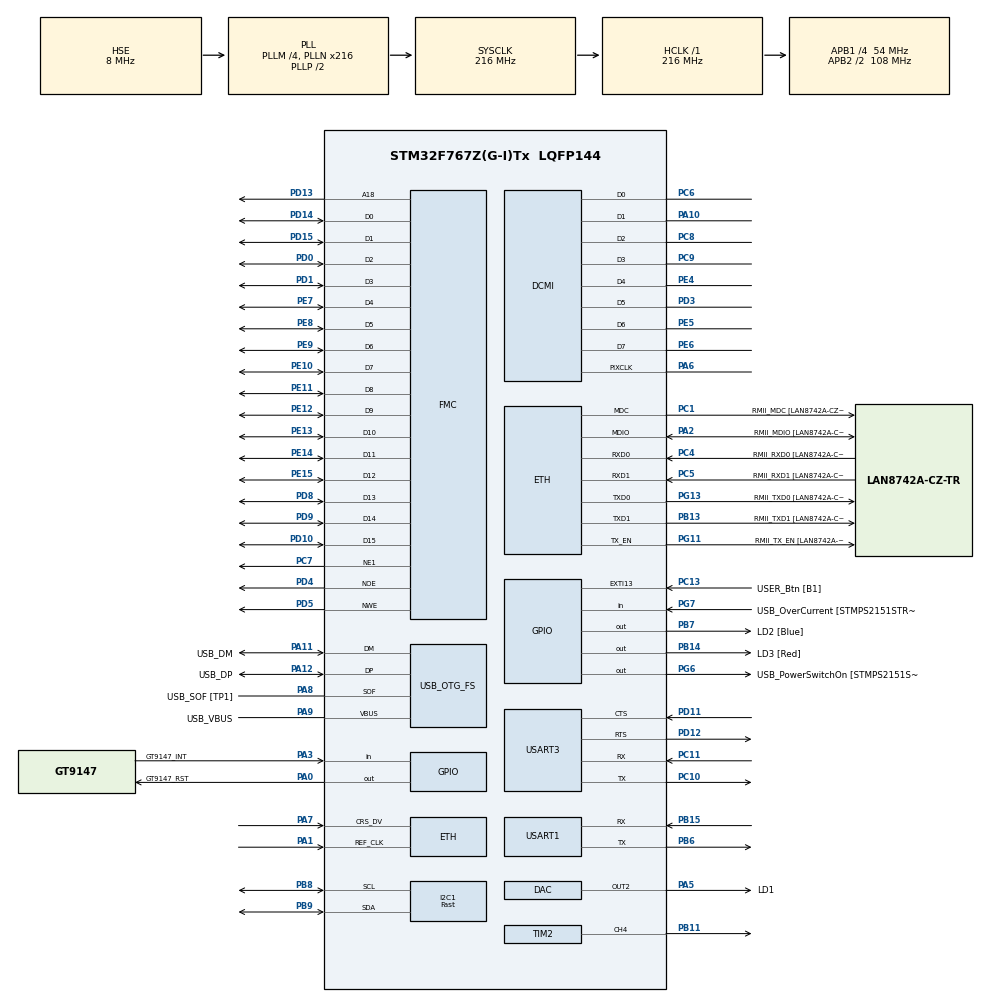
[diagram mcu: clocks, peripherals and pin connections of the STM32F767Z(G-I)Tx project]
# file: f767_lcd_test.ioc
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CORTEX_M7.ART_ACCLERATOR_ENABLE=1
CORTEX_M7.AccessPermission-Cortex_Memory_Protection_Unit_Region0_Settings=MPU_REGION_FULL_ACCESS
CORTEX_M7.BaseAddress-Cortex_Memory_Protection_Unit_Region0_Settings=0x20010000
CORTEX_M7.CPU_DCache=Enabled
CORTEX_M7.CPU_ICache=Enabled
CORTEX_M7.Enable-Cortex_Memory_Protection_Unit_Region0_Settings=MPU_REGION_ENABLE
CORTEX_M7.IsShareable-Cortex_Memory_Protection_Unit_Region0_Settings=MPU_ACCESS_SHAREABLE
CORTEX_M7.MPU_Control=MPU_HFNMI_PRIVDEF
CORTEX_M7.PREFETCH_ENABLE=1
CORTEX_M7.Size-Cortex_Memory_Protection_Unit_Region0_Settings=MPU_REGION_SIZE_4GB
DCMI.JPEGMode=DCMI_JPEG_DISABLE
ETH.MediaInterface=ETH_MEDIA_INTERFACE_RMII
FMC.DataSetupTime1=80
FMC.ExtendedAddressSetupTime1=1
FMC.ExtendedBusTurnAroundDuration1=1
FMC.ExtendedDataSetupTime1=2
FMC.ExtendedMode1=FMC_EXTENDED_MODE_ENABLE
I2C1.I2C_Speed_Mode=I2C_Fast
I2C1.Speed=400
I2C1.Timing=0x6000030D
Mcu.Family=STM32F7
Mcu.Name=STM32F767Z(G-I)Tx
Mcu.Package=LQFP144
NVIC.PriorityGroup=NVIC_PRIORITYGROUP_4
NVIC.USART3_IRQn=true\:0\:0\:false\:false\:true
PA0/WKUP.GPIO_Label=GT9147_RST
PA0/WKUP.PinState=GPIO_PIN_SET
PA0/WKUP.Signal=GPIO_Output
PA1.Mode=RMII
PA1.Signal=ETH_REF_CLK
PA10.Mode=Slave_8_bits_Embedded_Synchro
PA10.Signal=DCMI_D1
PA11.GPIO_Label=USB_DM
PA11.Mode=Host_Only
PA11.Signal=USB_OTG_FS_DM
PA12.GPIO_Label=USB_DP
PA12.Mode=Host_Only
PA12.Signal=USB_OTG_FS_DP
PA13.GPIO_Label=TMS
PA13.Mode=Trace_Asynchronous_SW
PA13.Signal=SYS_JTMS-SWDIO
PA14.GPIO_Label=TCK
PA14.Mode=Trace_Asynchronous_SW
PA14.Signal=SYS_JTCK-SWCLK
PA2.GPIO_Label=RMII_MDIO [LAN8742A-CZ-TR_MDIO]
PA2.Mode=RMII
PA2.Signal=ETH_MDIO
PA3.GPIO_Label=GT9147_INT
PA3.Signal=GPIO_Input
PA5.GPIO_Label=LD1
PA5.Signal=COMP_DAC2_group
PA6.Mode=Slave_8_bits_Embedded_Synchro
PA6.Signal=DCMI_PIXCLK
PA7.Mode=RMII
PA7.Signal=ETH_CRS_DV
PA8.GPIO_Label=USB_SOF [TP1]
PA8.Mode=Activate_SOF_FS
PA8.Signal=USB_OTG_FS_SOF
PA9.GPIO_Label=USB_VBUS
PA9.Mode=Activate_VBUS
PA9.Signal=USB_OTG_FS_VBUS
PB11.Signal=S_TIM2_CH4
PB13.GPIO_Label=RMII_TXD1 [LAN8742A-CZ-TR_TXD1]
PB13.Mode=RMII
PB13.Signal=ETH_TXD1
PB14.GPIO_Label=LD3 [Red]
PB14.Signal=GPIO_Output
PB15.Mode=Asynchronous
PB15.Signal=USART1_RX
PB3.GPIO_Label=SW0
PB3.Mode=Trace_Asynchronous_SW
PB3.Signal=SYS_JTDO-SWO
PB6.Mode=Asynchronous
PB6.Signal=USART1_TX
PB7.GPIO_Label=LD2 [Blue]
PB7.Signal=GPIO_Output
PB8.Mode=I2C
PB8.Signal=I2C1_SCL
PB9.Mode=I2C
PB9.Signal=I2C1_SDA
PC1.GPIO_Label=RMII_MDC [LAN8742A-CZ-TR_MDC]
PC1.Mode=RMII
PC1.Signal=ETH_MDC
PC10.Mode=Asynchronous
PC10.Signal=USART3_TX
PC11.Mode=Asynchronous
PC11.Signal=USART3_RX
PC13.GPIO_Label=USER_Btn [B1]
PC13.Signal=GPXTI13
PC14/OSC32_IN.Mode=LSE-External-Oscillator
PC14/OSC32_IN.Signal=RCC_OSC32_IN
PC15/OSC32_OUT.Mode=LSE-External-Oscillator
PC15/OSC32_OUT.Signal=RCC_OSC32_OUT
PC4.GPIO_Label=RMII_RXD0 [LAN8742A-CZ-TR_RXD0]
PC4.Mode=RMII
PC4.Signal=ETH_RXD0
PC5.GPIO_Label=RMII_RXD1 [LAN8742A-CZ-TR_RXD1]
PC5.Mode=RMII
PC5.Signal=ETH_RXD1
PC6.Mode=Slave_8_bits_Embedded_Synchro
PC6.Signal=DCMI_D0
PC7.Mode=NorPsramChipSelect1_1
PC7.Signal=FMC_NE1
PC8.Mode=Slave_8_bits_Embedded_Synchro
PC8.Signal=DCMI_D2
PC9.Mode=Slave_8_bits_Embedded_Synchro
PC9.Signal=DCMI_D3
PD0.Signal=FMC_D2_DA2
PD1.Signal=FMC_D3_DA3
PD10.Signal=FMC_D15_DA15
PD11.Mode=CTS_RTS
PD11.Signal=USART3_CTS
PD12.Mode=CTS_RTS
PD12.Signal=USART3_RTS
PD13.Signal=FMC_A18
PD14.Signal=FMC_D0_DA0
PD15.Signal=FMC_D1_DA1
PD3.Mode=Slave_8_bits_Embedded_Synchro
PD3.Signal=DCMI_D5
PD4.Signal=FMC_NOE
PD5.Signal=FMC_NWE
PD8.Signal=FMC_D13_DA13
PD9.Signal=FMC_D14_DA14
PE10.Signal=FMC_D7_DA7
PE11.Signal=FMC_D8_DA8
PE12.Signal=FMC_D9_DA9
PE13.Signal=FMC_D10_DA10
PE14.Signal=FMC_D11_DA11
PE15.Signal=FMC_D12_DA12
PE4.Mode=Slave_8_bits_Embedded_Synchro
PE4.Signal=DCMI_D4
PE5.Mode=Slave_8_bits_Embedded_Synchro
PE5.Signal=DCMI_D6
PE6.Mode=Slave_8_bits_Embedded_Synchro
PE6.Signal=DCMI_D7
PE7.Signal=FMC_D4_DA4
PE8.Signal=FMC_D5_DA5
PE9.Signal=FMC_D6_DA6
PG11.GPIO_Label=RMII_TX_EN [LAN8742A-CZ-TR_TXEN]
PG11.Mode=RMII
PG11.Signal=ETH_TX_EN
PG13.GPIO_Label=RMII_TXD0 [LAN8742A-CZ-TR_TXD0]
PG13.Mode=RMII
PG13.Signal=ETH_TXD0
PG6.GPIO_Label=USB_PowerSwitchOn [STMPS2151STR_EN]
PG6.Signal=GPIO_Output
PG7.GPIO_Label=USB_OverCurrent [STMPS2151STR_FAULT]
PG7.Signal=GPIO_Input
PH0/OSC_IN.GPIO_Label=MCO [STM32F103CBT6_PA8]
PH0/OSC_IN.Mode=HSE-External-Clock-Source
PH0/OSC_IN.Signal=RCC_OSC_IN
PH1/OSC_OUT.Mode=HSE-External-Clock-Source
PH1/OSC_OUT.Signal=RCC_OSC_OUT
ProjectManager.HeapSize=0x200
ProjectManager.StackSize=0x400
ProjectManager.TargetToolchain=SW4STM32
RCC.48MHZClocksFreq_Value=24000000
RCC.AHBFreq_Value=216000000
RCC.APB1CLKDivider=RCC_HCLK_DIV4
RCC.APB1Freq_Value=54000000
RCC.APB1TimFreq_Value=108000000
RCC.APB2CLKDivider=RCC_HCLK_DIV2
RCC.APB2Freq_Value=108000000
RCC.APB2TimFreq_Value=216000000
RCC.CortexFreq_Value=216000000
RCC.HCLKFreq_Value=216000000
RCC.HSE_VALUE=8000000
RCC.HSI_VALUE=16000000
RCC.PLLM=4
RCC.PLLMUL=RCC_PLL_MUL9
RCC.PLLN=216
RCC.PLLQ=9
RCC.PRESCALERUSB=RCC_USBCLKSOURCE_PLL_DIV1_5
RCC.SYSCLKFreq_VALUE=216000000
RCC.SYSCLKSource=RCC_SYSCLKSOURCE_PLLCLK
RCC.SYSCLKSourceVirtual=RCC_SYSCLKSOURCE_PLLCLK
RCC.USBFreq_Value=48000000
RCC.VCOOutputFreq_Value=432000000
SH.COMP_DAC2_group.0=DAC_OUT2,DAC_OUT2
SH.FMC_A18.0=FMC_A18,A18_1
SH.FMC_D0_DA0.0=FMC_D0,16b-d1
SH.FMC_D10_DA10.0=FMC_D10,16b-d1
SH.FMC_D11_DA11.0=FMC_D11,16b-d1
SH.FMC_D12_DA12.0=FMC_D12,16b-d1
SH.FMC_D13_DA13.0=FMC_D13,16b-d1
SH.FMC_D14_DA14.0=FMC_D14,16b-d1
SH.FMC_D15_DA15.0=FMC_D15,16b-d1
SH.FMC_D1_DA1.0=FMC_D1,16b-d1
SH.FMC_D2_DA2.0=FMC_D2,16b-d1
SH.FMC_D3_DA3.0=FMC_D3,16b-d1
SH.FMC_D4_DA4.0=FMC_D4,16b-d1
SH.FMC_D5_DA5.0=FMC_D5,16b-d1
SH.FMC_D6_DA6.0=FMC_D6,16b-d1
SH.FMC_D7_DA7.0=FMC_D7,16b-d1
SH.FMC_D8_DA8.0=FMC_D8,16b-d1
SH.FMC_D9_DA9.0=FMC_D9,16b-d1
SH.FMC_NOE.0=FMC_NOE,Lcd1
SH.FMC_NWE.0=FMC_NWE,Lcd1
SH.S_TIM2_CH4.0=TIM2_CH4,PWM Generation4 CH4
TIM2.AutoReloadPreload=TIM_AUTORELOAD_PRELOAD_ENABLE
TIM2.Channel-PWM\ Generation4\ CH4=TIM_CHANNEL_4
TIM2.OCFastMode_PWM-PWM\ Generation4\ CH4=TIM_OCFAST_ENABLE
TIM2.Period=200
TIM2.Pulse-PWM\ Generation4\ CH4=150
USART1.VirtualMode-Asynchronous=VM_ASYNC
USART1.WordLength=WORDLENGTH_8B
USART3.VirtualMode-Asynchronous=VM_ASYNC
USART3.WordLength=WORDLENGTH_8B
USB_OTG_FS.VirtualMode=Host_Only
USB_OTG_FS.phy_itface=HCD_PHY_EMBEDDED
VP_CRC_VS_CRC.Mode=CRC_Activate
VP_TIM2_VS_ClockSourceINT.Mode=Internal
board=NUCLEO-F767ZI

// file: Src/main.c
/**
  ******************************************************************************
  * File Name          : main.c
  * Description        : Main program body
  ******************************************************************************
  ** This notice applies to any and all portions of this file
  * that are not between comment pairs USER CODE BEGIN and
  * USER CODE END. Other portions of this file, whether
  * inserted by the user or by software development tools
  * are owned by their respective copyright owners.
  *
  * COPYRIGHT(c) 2017 STMicroelectronics
  *
  * Redistribution and use in source and binary forms, with or without modification,
  * are permitted provided that the following conditions are met:
  *   1. Redistributions of source code must retain the above copyright notice,
  *      this list of conditions and the following disclaimer.
  *   2. Redistributions in binary form must reproduce the above copyright notice,
  *      this list of conditions and the following disclaimer in the documentation
  *      and/or other materials provided with the distribution.
  *   3. Neither the name of STMicroelectronics nor the names of its contributors
  *      may be used to endorse or promote products derived from this software
  *      without specific prior written permission.
  *
  * THIS SOFTWARE IS PROVIDED BY THE COPYRIGHT HOLDERS AND CONTRIBUTORS "AS IS"
  * AND ANY EXPRESS OR IMPLIED WARRANTIES, INCLUDING, BUT NOT LIMITED TO, THE
  * IMPLIED WARRANTIES OF MERCHANTABILITY AND FITNESS FOR A PARTICULAR PURPOSE ARE
  * DISCLAIMED. IN NO EVENT SHALL THE COPYRIGHT HOLDER OR CONTRIBUTORS BE LIABLE
  * FOR ANY DIRECT, INDIRECT, INCIDENTAL, SPECIAL, EXEMPLARY, OR CONSEQUENTIAL
  * DAMAGES (INCLUDING, BUT NOT LIMITED TO, PROCUREMENT OF SUBSTITUTE GOODS OR
  * SERVICES; LOSS OF USE, DATA, OR PROFITS; OR BUSINESS INTERRUPTION) HOWEVER
  * CAUSED AND ON ANY THEORY OF LIABILITY, WHETHER IN CONTRACT, STRICT LIABILITY,
  * OR TORT (INCLUDING NEGLIGENCE OR OTHERWISE) ARISING IN ANY WAY OUT OF THE USE
  * OF THIS SOFTWARE, EVEN IF ADVISED OF THE POSSIBILITY OF SUCH DAMAGE.
  *
  ******************************************************************************
  */
#include "main.h"
#include "stm32f7xx_hal.h"
#include "crc.h"
#include "dac.h"
#include "dcmi.h"
#include "eth.h"
#include "i2c.h"
#include "tim.h"
#include "usart.h"
#include "usb_otg.h"
#include "gpio.h"
#include "fmc.h"

/* USER CODE BEGIN Includes */
#include "stdio.h"
#include "system/init.h"
#include "system/tasks.h"
/* USER CODE END Includes */

/* USER CODE BEGIN PV */
/* Private variables ---------------------------------------------------------*/

/* USER CODE END PV */

void SystemClock_Config(void);
static void MPU_Config(void);

/* USER CODE BEGIN PFP */
/* Private function prototypes -----------------------------------------------*/

/* USER CODE END PFP */

/* USER CODE BEGIN 0 */
extern UART_HandleTypeDef huart1;
/**
  * @brief  Retargets the C library printf function to the USART.
  * @param  None
  * @retval None
  */
int __io_putchar(int ch)
{
  /* Place your implementation of fputc here */
  /* e.g. write a character to the USART1 and Loop until the end of transmission */
  HAL_UART_Transmit(&huart1, (uint8_t *)&ch, 1, 0xFFFF);

  return ch;
}
/* USER CODE END 0 */

int main(void)
{

  /* MPU Configuration----------------------------------------------------------*/
  MPU_Config();

  /* Enable I-Cache-------------------------------------------------------------*/
  SCB_EnableICache();

  /* Enable D-Cache-------------------------------------------------------------*/
  SCB_EnableDCache();

  /* MCU Configuration----------------------------------------------------------*/

  /* Reset of all peripherals, Initializes the Flash interface and the Systick. */
  HAL_Init();

  /* Configure the system clock */
  SystemClock_Config();

  /* Initialize all configured peripherals */
  MX_GPIO_Init();
  MX_FMC_Init();
  MX_DAC_Init();
  MX_I2C1_Init();
  MX_USART1_UART_Init();
  MX_USART3_UART_Init();
  MX_CRC_Init();
  MX_ETH_Init();
  MX_TIM2_Init();
  MX_USB_OTG_FS_HCD_Init();
  MX_DCMI_Init();

  /* USER CODE BEGIN 2 */
  device_init();
  driver_init();

  printf("UART Printf Example: retarget the C library printf function to the UART\r\n");
  printf("** Test finished successfully. ** \r\n");

  tasks_init();
  /* USER CODE END 2 */

  /* Infinite loop */
  while (1)
  {

  /* USER CODE BEGIN 3 */
	  tasks_loop();
	  device_suspend();
  }
  /* USER CODE END 3 */

}

/** System Clock Configuration
*/
void SystemClock_Config(void)
{

  RCC_OscInitTypeDef RCC_OscInitStruct;
  RCC_ClkInitTypeDef RCC_ClkInitStruct;
  RCC_PeriphCLKInitTypeDef PeriphClkInitStruct;

    /**Configure the main internal regulator output voltage
    */
  __HAL_RCC_PWR_CLK_ENABLE();

  __HAL_PWR_VOLTAGESCALING_CONFIG(PWR_REGULATOR_VOLTAGE_SCALE1);

    /**Initializes the CPU, AHB and APB busses clocks
    */
  RCC_OscInitStruct.OscillatorType = RCC_OSCILLATORTYPE_HSE;
  RCC_OscInitStruct.HSEState = RCC_HSE_BYPASS;
  RCC_OscInitStruct.PLL.PLLState = RCC_PLL_ON;
  RCC_OscInitStruct.PLL.PLLSource = RCC_PLLSOURCE_HSE;
  RCC_OscInitStruct.PLL.PLLM = 4;
  RCC_OscInitStruct.PLL.PLLN = 216;
  RCC_OscInitStruct.PLL.PLLP = RCC_PLLP_DIV2;
  RCC_OscInitStruct.PLL.PLLQ = 9;
  if (HAL_RCC_OscConfig(&RCC_OscInitStruct) != HAL_OK)
  {
    _Error_Handler(__FILE__, __LINE__);
  }

    /**Activate the Over-Drive mode
    */
  if (HAL_PWREx_EnableOverDrive() != HAL_OK)
  {
    _Error_Handler(__FILE__, __LINE__);
  }

    /**Initializes the CPU, AHB and APB busses clocks
    */
  RCC_ClkInitStruct.ClockType = RCC_CLOCKTYPE_HCLK|RCC_CLOCKTYPE_SYSCLK
                              |RCC_CLOCKTYPE_PCLK1|RCC_CLOCKTYPE_PCLK2;
  RCC_ClkInitStruct.SYSCLKSource = RCC_SYSCLKSOURCE_PLLCLK;
  RCC_ClkInitStruct.AHBCLKDivider = RCC_SYSCLK_DIV1;
  RCC_ClkInitStruct.APB1CLKDivider = RCC_HCLK_DIV4;
  RCC_ClkInitStruct.APB2CLKDivider = RCC_HCLK_DIV2;

  if (HAL_RCC_ClockConfig(&RCC_ClkInitStruct, FLASH_LATENCY_7) != HAL_OK)
  {
    _Error_Handler(__FILE__, __LINE__);
  }

  PeriphClkInitStruct.PeriphClockSelection = RCC_PERIPHCLK_USART1|RCC_PERIPHCLK_USART3
                              |RCC_PERIPHCLK_I2C1|RCC_PERIPHCLK_CLK48;
  PeriphClkInitStruct.Usart1ClockSelection = RCC_USART1CLKSOURCE_PCLK2;
  PeriphClkInitStruct.Usart3ClockSelection = RCC_USART3CLKSOURCE_PCLK1;
  PeriphClkInitStruct.I2c1ClockSelection = RCC_I2C1CLKSOURCE_PCLK1;
  PeriphClkInitStruct.Clk48ClockSelection = RCC_CLK48SOURCE_PLL;
  if (HAL_RCCEx_PeriphCLKConfig(&PeriphClkInitStruct) != HAL_OK)
  {
    _Error_Handler(__FILE__, __LINE__);
  }

    /**Configure the Systick interrupt time
    */
  HAL_SYSTICK_Config(HAL_RCC_GetHCLKFreq()/1000);

    /**Configure the Systick
    */
  HAL_SYSTICK_CLKSourceConfig(SYSTICK_CLKSOURCE_HCLK);

  /* SysTick_IRQn interrupt configuration */
  HAL_NVIC_SetPriority(SysTick_IRQn, 0, 0);
}

/* MPU Configuration */

void MPU_Config(void)
{
  MPU_Region_InitTypeDef MPU_InitStruct;

  /* Disables the MPU */
  HAL_MPU_Disable();
    /**Initializes and configures the Region and the memory to be protected
    */
  MPU_InitStruct.Enable = MPU_REGION_ENABLE;
  MPU_InitStruct.Number = MPU_REGION_NUMBER0;
  MPU_InitStruct.BaseAddress = 0x20010000;
  MPU_InitStruct.Size = MPU_REGION_SIZE_4GB;
  MPU_InitStruct.SubRegionDisable = 0x0;
  MPU_InitStruct.TypeExtField = MPU_TEX_LEVEL0;
  MPU_InitStruct.AccessPermission = MPU_REGION_FULL_ACCESS;
  MPU_InitStruct.DisableExec = MPU_INSTRUCTION_ACCESS_ENABLE;
  MPU_InitStruct.IsShareable = MPU_ACCESS_SHAREABLE;
  MPU_InitStruct.IsCacheable = MPU_ACCESS_NOT_CACHEABLE;
  MPU_InitStruct.IsBufferable = MPU_ACCESS_NOT_BUFFERABLE;

  HAL_MPU_ConfigRegion(&MPU_InitStruct);

  /* Enables the MPU */
  HAL_MPU_Enable(MPU_HFNMI_PRIVDEF);

}

void _Error_Handler(char * file, int line)
{
  while(1)
  {
  }
}

/************************ (C) COPYRIGHT STMicroelectronics *****END OF FILE****/
